# HDSC_HC32F120F6TA register map
Vendor: HDSC Co.,Ltd.; Series: ARMCM0P; File version: 1.0
CPU: CM0P r0p1, little endian, no MPU, no FPU, 4 interrupt priority bits
Registers are 32-bit, read-write, reset 0x0 unless marked. A register's access mark holds for its fields unless they carry their own. Offsets are from the block's base; [hi:lo] are bit positions; {n}, {i} and the like mark numbered series; 'fields as' and 'values as' point back to an identical list.

## I2C
Base 0x40004800
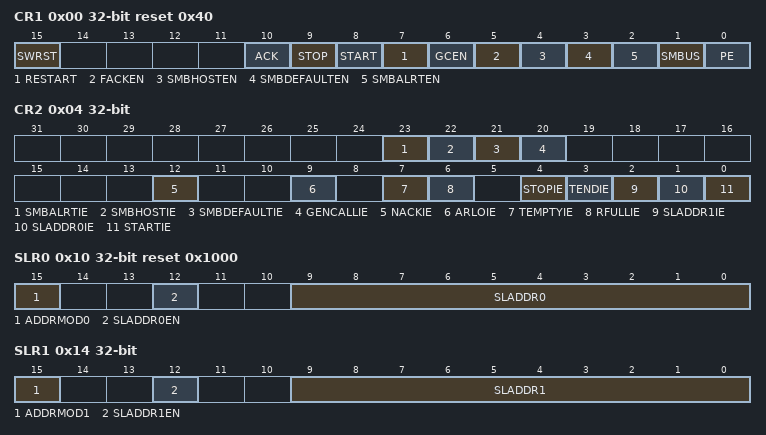
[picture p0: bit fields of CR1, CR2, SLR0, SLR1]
0x00 CR1 reset 0x40
  [15] SWRST, [10] ACK, [9] STOP, [8] START, [7] RESTART, [6] GCEN, [5] FACKEN, [4] SMBHOSTEN, [3] SMBDEFAULTEN, [2] SMBALRTEN, [1] SMBUS, [0] PE
0x04 CR2
  [23] SMBALRTIE, [22] SMBHOSTIE, [21] SMBDEFAULTIE, [20] GENCALLIE, [12] NACKIE, [9] ARLOIE, [7] TEMPTYIE, [6] RFULLIE, [4] STOPIE, [3] TENDIE, [2] SLADDR1IE, [1] SLADDR0IE, [0] STARTIE
0x10 SLR0 reset 0x1000
  [15] ADDRMOD0, [12] SLADDR0EN, [9:0] SLADDR0
0x14 SLR1
  [15] ADDRMOD1, [12] SLADDR1EN, [9:0] SLADDR1
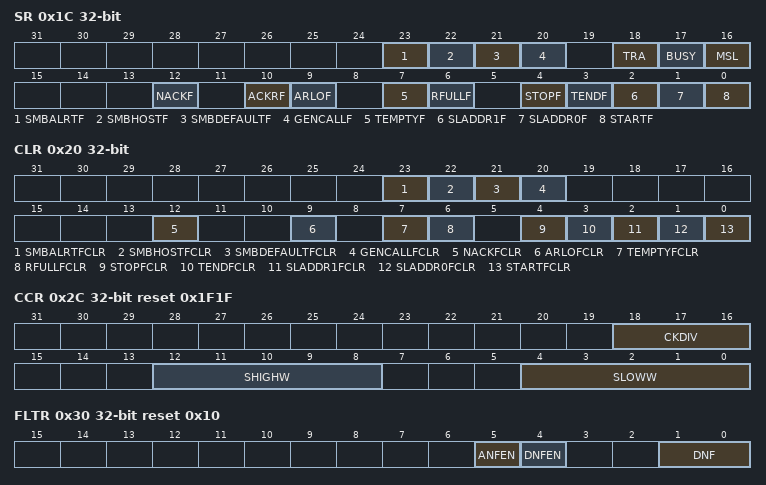
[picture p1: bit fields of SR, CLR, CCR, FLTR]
0x1C SR ro
  [23] SMBALRTF, [22] SMBHOSTF, [21] SMBDEFAULTF, [20] GENCALLF, [18] TRA rw, [17] BUSY, [16] MSL rw, [12] NACKF, [10] ACKRF, [9] ARLOF, [7] TEMPTYF, [6] RFULLF, [4] STOPF, [3] TENDF, [2] SLADDR1F, [1] SLADDR0F, [0] STARTF
0x20 CLR wo
  [23] SMBALRTFCLR, [22] SMBHOSTFCLR, [21] SMBDEFAULTFCLR, [20] GENCALLFCLR, [12] NACKFCLR, [9] ARLOFCLR, [7] TEMPTYFCLR, [6] RFULLFCLR, [4] STOPFCLR, [3] TENDFCLR, [2] SLADDR1FCLR, [1] SLADDR0FCLR, [0] STARTFCLR
0x24 DTR 8-bit reset 0xFF
  [7:0] DT
0x28 DRR 8-bit
  [7:0] DR
0x2C CCR reset 0x1F1F
  [18:16] CKDIV, [12:8] SHIGHW, [4:0] SLOWW
0x30 FLTR reset 0x10
  [5] ANFEN, [4] DNFEN, [1:0] DNF

## ICG
Base 0x000000C0
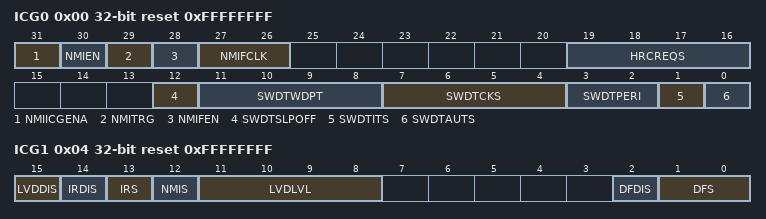
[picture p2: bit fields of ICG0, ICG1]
0x00 ICG0 ro reset 0xFFFFFFFF
  [31] NMIICGENA, [30] NMIEN, [29] NMITRG, [28] NMIFEN, [27:26] NMIFCLK, [19:16] HRCREQS, [12] SWDTSLPOFF, [11:8] SWDTWDPT, [7:4] SWDTCKS, [3:2] SWDTPERI, [1] SWDTITS, [0] SWDTAUTS
0x04 ICG1 ro reset 0xFFFFFFFF
  [15] LVDDIS, [14] IRDIS, [13] IRS, [12] NMIS, [11:8] LVDLVL, [2] DFDIS, [1:0] DFS
{0x0+4i} ICG{i} ro reset 0xFFFFFFFF (reset mask 0x0) (i=2..6)

## INTC
Base 0x40011000
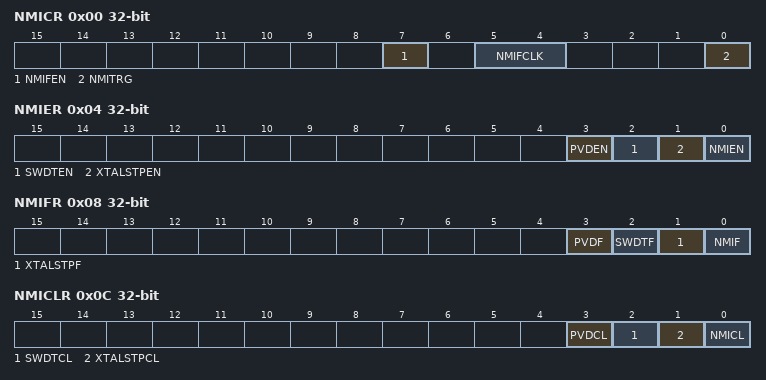
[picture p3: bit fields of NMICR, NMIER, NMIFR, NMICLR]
0x00 NMICR
  [7] NMIFEN, [5:4] NMIFCLK, [0] NMITRG
0x04 NMIER
  [3] PVDEN, [2] SWDTEN, [1] XTALSTPEN, [0] NMIEN
0x08 NMIFR ro
  [3] PVDF, [2] SWDTF, [1] XTALSTPF, [0] NMIF
0x0C NMICLR
  [3] PVDCL, [2] SWDTCL, [1] XTALSTPCL, [0] NMICL
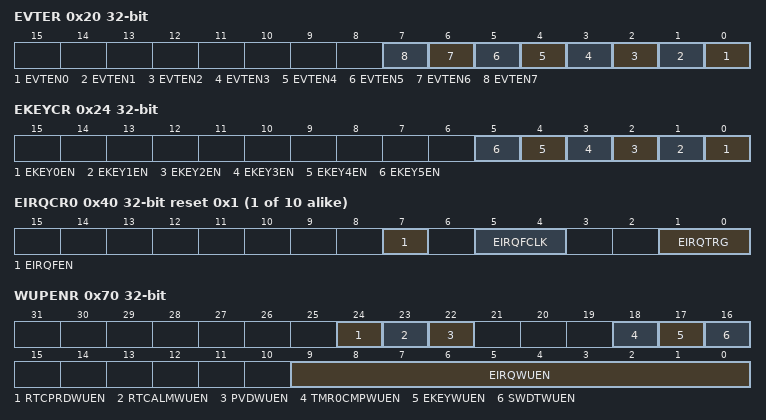
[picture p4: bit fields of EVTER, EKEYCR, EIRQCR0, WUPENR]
0x20 EVTER
  [n] EVTEN{n} (n=0..7)
0x24 EKEYCR
  [n] EKEY{n}EN (n=0..5)
0x3C FPRCR
  [7:0] FPRC
{0x40+4i} EIRQCR{i} reset 0x1 (i=0..9)
  [7] EIRQFEN, [5:4] EIRQFCLK, [1:0] EIRQTRG
0x70 WUPENR
  [24] RTCPRDWUEN, [23] RTCALMWUEN, [22] PVDWUEN, [18] TMR0CMPWUEN, [17] EKEYWUEN, [16] SWDTWUEN, [9:0] EIRQWUEN
0x74 EIRQFR
  [9:0] EIRQF
0x78 EIRQCLR
  [9:0] EIRQCL
{0x80+4i} ISELAR{i} (i=8..23)
  [3:0] ISEL
{0x80+4i} ISELBR{i} (i=24..31)
  [15:1] ISEL

## PORT
Base 0x40013800
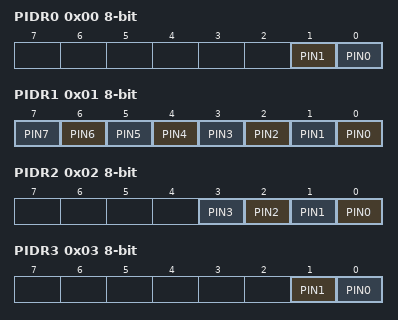
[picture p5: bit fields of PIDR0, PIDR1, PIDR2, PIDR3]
0x00 PIDR0 8-bit ro
  [1] PIN1, [0] PIN0
0x01 PIDR1 8-bit ro
  [n] PIN{n} (n=0..7)
0x02 PIDR2 8-bit ro
  [n] PIN{n} (n=0..3)
0x03 PIDR3 8-bit ro
  [1] PIN1, [0] PIN0
0x04 PIDR4 8-bit ro
  [0] PIN0
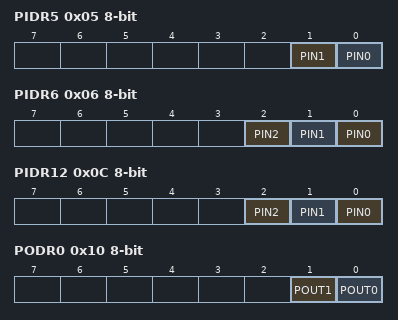
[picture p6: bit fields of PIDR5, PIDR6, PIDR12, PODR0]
0x05 PIDR5 8-bit ro
  [1] PIN1, [0] PIN0
0x06 PIDR6 8-bit ro
  [2] PIN2, [1] PIN1, [0] PIN0
0x07 PIDR7 8-bit ro
  [0] PIN0
0x0C PIDR12 8-bit ro
  [2] PIN2, [1] PIN1, [0] PIN0
0x0D PIDR13 8-bit ro
  [7] PIN7
0x0E PIDR14 8-bit ro
  [7] PIN7
0x10 PODR0 8-bit
  [1] POUT1, [0] POUT0
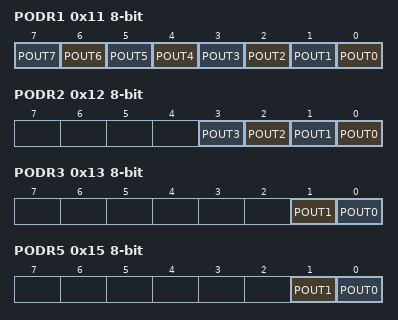
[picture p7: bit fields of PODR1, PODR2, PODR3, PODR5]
0x11 PODR1 8-bit
  [n] POUT{n} (n=0..7)
0x12 PODR2 8-bit
  [n] POUT{n} (n=0..3)
0x13 PODR3 8-bit
  [1] POUT1, [0] POUT0
0x14 PODR4 8-bit
  [0] POUT0
0x15 PODR5 8-bit
  [1] POUT1, [0] POUT0
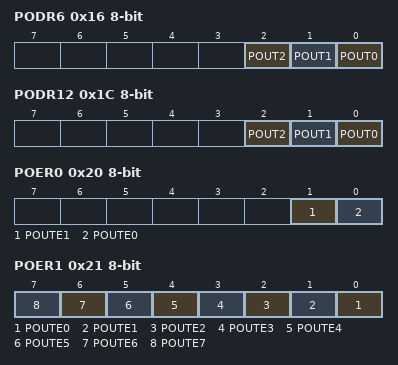
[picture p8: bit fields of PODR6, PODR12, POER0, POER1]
0x16 PODR6 8-bit
  [2] POUT2, [1] POUT1, [0] POUT0
0x17 PODR7 8-bit
  [0] POUT0
0x1C PODR12 8-bit
  [2] POUT2, [1] POUT1, [0] POUT0
0x1D PODR13 8-bit
  [7] POUT7
0x1E PODR14 8-bit
  [7] POUT7
0x20 POER0 8-bit
  [1] POUTE1, [0] POUTE0
0x21 POER1 8-bit
  [n] POUTE{n} (n=0..7)
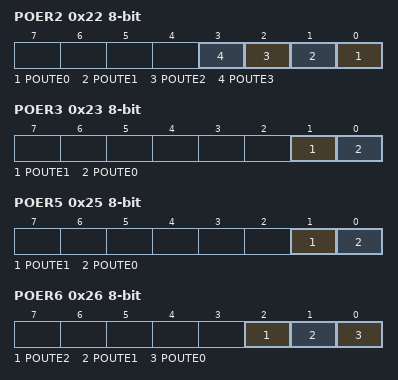
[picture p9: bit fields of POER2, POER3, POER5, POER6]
0x22 POER2 8-bit
  [n] POUTE{n} (n=0..3)
0x23 POER3 8-bit
  [1] POUTE1, [0] POUTE0
0x24 POER4 8-bit
  [0] POUTE0
0x25 POER5 8-bit
  [1] POUTE1, [0] POUTE0
0x26 POER6 8-bit
  [2] POUTE2, [1] POUTE1, [0] POUTE0
0x27 POER7 8-bit
  [0] POUTE0
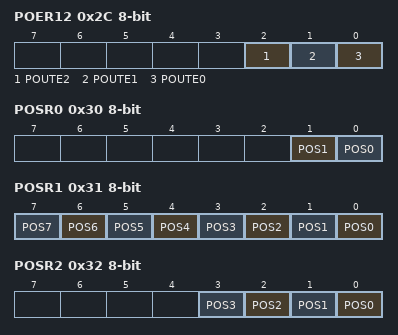
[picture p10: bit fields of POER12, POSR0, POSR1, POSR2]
0x2C POER12 8-bit
  [2] POUTE2, [1] POUTE1, [0] POUTE0
0x2D POER13 8-bit
  [7] POUTE7
0x2E POER14 8-bit
  [7] POUTE7
0x30 POSR0 8-bit wo
  [1] POS1, [0] POS0
0x31 POSR1 8-bit wo
  [n] POS{n} (n=0..7)
0x32 POSR2 8-bit wo
  [n] POS{n} (n=0..3)
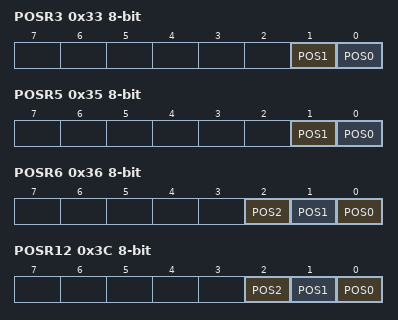
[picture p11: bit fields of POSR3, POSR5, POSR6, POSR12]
0x33 POSR3 8-bit wo
  [1] POS1, [0] POS0
0x34 POSR4 8-bit wo
  [0] POS0
0x35 POSR5 8-bit wo
  [1] POS1, [0] POS0
0x36 POSR6 8-bit wo
  [2] POS2, [1] POS1, [0] POS0
0x37 POSR7 8-bit wo
  [0] POS0
0x3C POSR12 8-bit wo
  [2] POS2, [1] POS1, [0] POS0
0x3D POSR13 8-bit wo
  [7] POS7
0x3E POSR14 8-bit wo
  [7] POS7
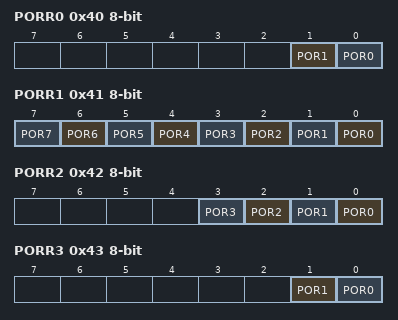
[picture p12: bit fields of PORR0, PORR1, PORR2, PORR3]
0x40 PORR0 8-bit wo
  [1] POR1, [0] POR0
0x41 PORR1 8-bit wo
  [n] POR{n} (n=0..7)
0x42 PORR2 8-bit wo
  [n] POR{n} (n=0..3)
0x43 PORR3 8-bit wo
  [1] POR1, [0] POR0
0x44 PORR4 8-bit wo
  [0] POR0
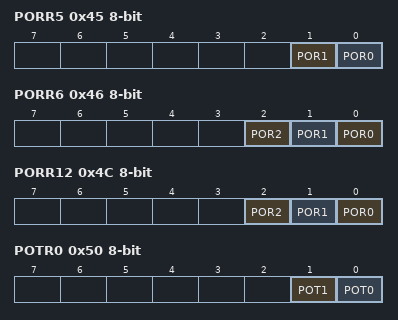
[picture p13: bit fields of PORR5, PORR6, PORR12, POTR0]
0x45 PORR5 8-bit wo
  [1] POR1, [0] POR0
0x46 PORR6 8-bit wo
  [2] POR2, [1] POR1, [0] POR0
0x47 PORR7 8-bit wo
  [0] POR0
0x4C PORR12 8-bit wo
  [2] POR2, [1] POR1, [0] POR0
0x4D PORR13 8-bit wo
  [7] POR7
0x4E PORR14 8-bit wo
  [7] POR7
0x50 POTR0 8-bit wo
  [1] POT1, [0] POT0
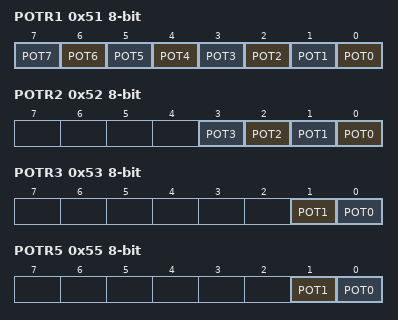
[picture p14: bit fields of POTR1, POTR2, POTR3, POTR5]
0x51 POTR1 8-bit wo
  [n] POT{n} (n=0..7)
0x52 POTR2 8-bit wo
  [n] POT{n} (n=0..3)
0x53 POTR3 8-bit wo
  [1] POT1, [0] POT0
0x54 POTR4 8-bit wo
  [0] POT0
0x55 POTR5 8-bit wo
  [1] POT1, [0] POT0
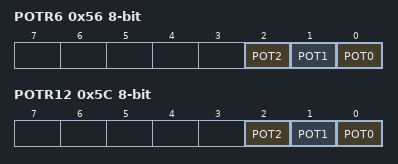
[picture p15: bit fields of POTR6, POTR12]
0x56 POTR6 8-bit wo
  [2] POT2, [1] POT1, [0] POT0
0x57 POTR7 8-bit wo
  [0] POT0
0x5C POTR12 8-bit wo
  [2] POT2, [1] POT1, [0] POT0
0x5D POTR13 8-bit wo
  [7] POT7
0x5E POTR14 8-bit wo
  [7] POT7
0x400 PCR00 16-bit
  [14:12] FSEL, [11] INTE, [10] CINSEL, [9] INVE, [8] PIN ro, [6] PUU, [5] LTE, [4] DRV, [2] NOD, [1] POUTE, [0] POUT
0x402 PCR01 16-bit
  fields as PCR00
{0x3FC+2i} PCR{i} 16-bit (i=10..17)
  fields as PCR00
{0x3F8+2i} PCR{i} 16-bit (i=20..23)
  fields as PCR00
0x430 PCR30 16-bit
  fields as PCR00
0x432 PCR31 16-bit
  fields as PCR00
0x440 PCR40 16-bit
  fields as PCR00
0x450 PCR50 16-bit
  fields as PCR00
0x452 PCR51 16-bit
  fields as PCR00
{0x3E8+2i} PCR{i} 16-bit (i=60..62)
  fields as PCR00
0x470 PCR70 16-bit
  fields as PCR00
{0x3D0+2i} PCR{i} 16-bit (i=120..122)
  fields as PCR00
0x4DE PCR137 16-bit
  fields as PCR00
0x4EE PCR147 16-bit
  fields as PCR00
0x500 PSPCR 16-bit reset 0x3
  [1:0] SPFE
0x504 PCCR 16-bit reset 0x4000
  [15:14] RDWT
0x506 PINAER 16-bit
  [14] PINAE14, [13] PINAE13, [12] PINAE12, [n] PINAE{n} (n=0..7)
0x508 PWPR 16-bit
  [15:8] WP wo, [0] WE
